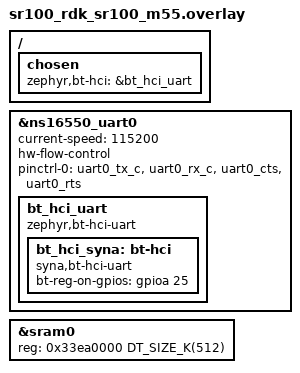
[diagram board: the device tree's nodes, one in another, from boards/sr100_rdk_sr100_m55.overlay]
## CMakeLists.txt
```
# Copyright (c) 2026 Synaptics Incorporated
#
# SPDX-License-Identifier: Apache-2.0

cmake_minimum_required(VERSION 3.20.0)
find_package(Zephyr REQUIRED HINTS $ENV{ZEPHYR_BASE})
project(bap_unicast_client)

target_include_directories(app PRIVATE
	$ENV{ZEPHYR_BASE}/samples/bluetooth/bap_unicast_client/src/
)

target_sources(app PRIVATE
	src/main.c
	src/stream_tx.c
)

# Use upstream LC3 encoder when liblc3 is available; fall back to stub otherwise
if(CONFIG_LIBLC3)
  target_sources(app PRIVATE
    $ENV{ZEPHYR_BASE}/samples/bluetooth/bap_unicast_client/src/stream_lc3.c
  )
else()
  target_sources(app PRIVATE src/stream_lc3.c)
endif()
```

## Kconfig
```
# Copyright (c) 2025 Nordic Semiconductor ASA
# Copyright (c) 2026 Synaptics Incorporated
#
# SPDX-License-Identifier: Apache-2.0

mainmenu "Bluetooth: BAP Unicast Client (SR110 RDK)"

config INFO_REPORTING_INTERVAL
	int "Number of SDUs received between each information report"
	default 1000
	help
	  Determines how often information about received data is logged.
	  Set to 0 to disable reporting.

config BT_BAP_AUTO_CONNECT
	bool "Auto-connect without user interaction"
	default n
	help
	  When enabled, scan_and_connect() selects a device automatically
	  after the scan timeout without waiting for console input.

	  If CONFIG_BT_BAP_AUTO_CONNECT_ADDR is non-empty, the sample
	  connects directly to that address (skipping the scan list).
	  Otherwise it selects the device with the strongest RSSI from
	  the scan results.

	  Useful for automated testing where no one is at the UART console
	  to type a device selection.

config BT_BAP_AUTO_CONNECT_ADDR
	string "Fixed peer Bluetooth address for auto-connect"
	default ""
	help
	  Used only when CONFIG_BT_BAP_AUTO_CONNECT=y.
	  If non-empty, the sample will connect directly to this address
	  (format: "XX:XX:XX:XX:XX:XX").
	  Leave empty to auto-select the device with the strongest RSSI.

source "Kconfig.zephyr"
```

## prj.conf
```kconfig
CONFIG_BT=y
CONFIG_LOG=y
CONFIG_BT_SMP=y
CONFIG_BT_CENTRAL=y
CONFIG_BT_ISO_CENTRAL=y
CONFIG_BT_GATT_CLIENT=y
CONFIG_BT_GATT_AUTO_DISCOVER_CCC=y
CONFIG_BT_GATT_AUTO_UPDATE_MTU=y
CONFIG_UTF8=y
CONFIG_BT_AUDIO=y
CONFIG_BT_BAP_UNICAST_CLIENT=y
CONFIG_BT_ISO_TX_BUF_COUNT=8
CONFIG_BT_ISO_MAX_CHAN=4
CONFIG_BT_BAP_UNICAST_CLIENT_GROUP_STREAM_COUNT=4
CONFIG_BT_BAP_UNICAST_CLIENT_ASE_SNK_COUNT=2
CONFIG_BT_BAP_UNICAST_CLIENT_ASE_SRC_COUNT=0
CONFIG_BT_KEYS_OVERWRITE_OLDEST=y
CONFIG_BT_EXT_ADV=y

# LC3 encoder — generates sine wave audio sent over ISO
CONFIG_LIBLC3=y
CONFIG_FPU=y
CONFIG_FPU_SHARING=y

# LC3 TX thread needs a larger stack (encoder uses ~2KB)
CONFIG_BT_ISO_TX_MTU=155

# Interactive device selection
CONFIG_CONSOLE_SUBSYS=y
CONFIG_CONSOLE_GETLINE=y

# ── SR110 + SYNA hardware ─────────────────────────────────────────────────
CONFIG_BT_H4=y
CONFIG_BT_HCI_SYNA=y
CONFIG_GPIO=y
CONFIG_UART_INTERRUPT_DRIVEN=y
CONFIG_UART_NS16550_VARIANT_NS16750=y
CONFIG_SRAM_SIZE=512
CONFIG_MAIN_STACK_SIZE=4096
CONFIG_BT_RX_STACK_SIZE=4096
CONFIG_BT_BUF_CMD_TX_SIZE=255

# Debug: enable ISO and BAP ISO logging to diagnose data path setup failures
CONFIG_BT_ISO_LOG_LEVEL_DBG=y
CONFIG_BT_BAP_ISO_LOG_LEVEL_DBG=y
CONFIG_XIP=n
```

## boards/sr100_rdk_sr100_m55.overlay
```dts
/*
 * Copyright (c) 2026 Synaptics Incorporated
 *
 * SPDX-License-Identifier: Apache-2.0
 */

/ {
	chosen {
		zephyr,bt-hci = &bt_hci_uart;
	};
};

&ns16550_uart0 {
	status = "okay";
	current-speed = <115200>;
	hw-flow-control;
	pinctrl-0 = <&uart0_tx_c &uart0_rx_c &uart0_cts &uart0_rts>;
	pinctrl-names = "default";

	bt_hci_uart: bt_hci_uart {
		compatible = "zephyr,bt-hci-uart";
		status = "okay";

		bt_hci_syna: bt-hci {
			compatible = "syna,bt-hci-uart";
			status = "okay";
			bt-reg-on-gpios = <&gpioa 25 GPIO_ACTIVE_HIGH>;
		};
	};
};

/*
 * Extend SRAM to 512KB (0x33ea0000..0x33F20000).
 * 384KB is enough for normal BT samples, but bap_unicast_client with
 * liblc3 needs ~88KB extra for the LC3 lookup tables (rodata).
 * 0x33F20000 is the OpenOCD WORKAREA_ADDR — safe boundary for runtime.
 */
&sram0 {
	reg = <0x33ea0000 DT_SIZE_K(512)>;
	ranges = <0x0 0x33ea0000 DT_SIZE_K(512)>;
};
```

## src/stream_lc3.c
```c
/*
 * Copyright (c) 2026 Synaptics Incorporated
 *
 * SPDX-License-Identifier: Apache-2.0
 */

#include <errno.h>
#include <zephyr/net_buf.h>

/* Forward declaration matching stream_lc3.h opaque type */
struct tx_stream;

int stream_lc3_init(struct tx_stream *stream)
{
(void)stream;
return -ENOTSUP;
}

void stream_lc3_add_data(struct tx_stream *stream, struct net_buf *buf)
{
(void)stream;
(void)buf;
}
```

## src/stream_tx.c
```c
/*
 * Copyright (c) 2024-2025 Nordic Semiconductor ASA
 *
 * SPDX-License-Identifier: Apache-2.0
 */

#include <autoconf.h>
#include <errno.h>
#include <stdbool.h>
#include <stddef.h>
#include <stdint.h>

#include <zephyr/bluetooth/audio/cap.h>
#include <zephyr/bluetooth/audio/bap.h>
#include <zephyr/bluetooth/bluetooth.h>
#include <zephyr/bluetooth/hci_types.h>
#include <zephyr/bluetooth/iso.h>
#include <zephyr/kernel.h>
#include <zephyr/kernel/thread_stack.h>
#include <zephyr/logging/log.h>
#include <zephyr/logging/log_core.h>
#include <zephyr/net_buf.h>
#include <zephyr/sys/__assert.h>
#include <zephyr/sys/byteorder.h>
#include <zephyr/sys/util.h>
#include <zephyr/sys/util_macro.h>
#include <zephyr/types.h>

#include "stream_lc3.h"
#include "stream_tx.h"

LOG_MODULE_REGISTER(stream_tx, LOG_LEVEL_INF);

static struct tx_stream tx_streams[CONFIG_BT_BAP_UNICAST_CLIENT_ASE_SNK_COUNT];

static bool stream_is_streaming(const struct bt_bap_stream *bap_stream)
{
	struct bt_bap_ep_info ep_info;
	int err;

	if (bap_stream == NULL) {
		return false;
	}

	/* No-op if stream is not configured */
	if (bap_stream->ep == NULL) {
		return false;
	}

	err = bt_bap_ep_get_info(bap_stream->ep, &ep_info);
	if (err != 0) {
		return false;
	}

	return ep_info.state == BT_BAP_EP_STATE_STREAMING;
}

static void tx_thread_func(void *arg1, void *arg2, void *arg3)
{
	NET_BUF_POOL_FIXED_DEFINE(tx_pool, CONFIG_BT_ISO_TX_BUF_COUNT,
				  BT_ISO_SDU_BUF_SIZE(CONFIG_BT_ISO_TX_MTU),
				  CONFIG_BT_CONN_TX_USER_DATA_SIZE, NULL);
	static uint8_t mock_data[CONFIG_BT_ISO_TX_MTU];

	for (size_t i = 0U; i < ARRAY_SIZE(mock_data); i++) {
		mock_data[i] = (uint8_t)i;
	}

	/* This loop will attempt to send on all streams in the streaming state in a round robin
	 * fashion.
	 * The TX is controlled by the number of buffers configured, and increasing
	 * CONFIG_BT_ISO_TX_BUF_COUNT will allow for more streams in parallel, or to submit more
	 * buffers per stream.
	 * Once a buffer has been freed by the stack, it triggers the next TX.
	 */
	while (true) {
		bool any_sent = false;

		for (size_t i = 0U; i < ARRAY_SIZE(tx_streams); i++) {
			struct bt_bap_stream *bap_stream = tx_streams[i].bap_stream;

			if (stream_is_streaming(bap_stream)) {
				uint16_t sdu_len;
				struct net_buf *buf;

				buf = net_buf_alloc(&tx_pool, K_NO_WAIT);
				if (buf == NULL) {
					/* No buffer available for this stream right now.
					 * Skip so the other stream is not starved.
					 */
					continue;
				}
				net_buf_reserve(buf, BT_ISO_CHAN_SEND_RESERVE);

				if (IS_ENABLED(CONFIG_LIBLC3) &&
				    bap_stream->codec_cfg->id == BT_HCI_CODING_FORMAT_LC3) {
					stream_lc3_add_data(&tx_streams[i], buf);
				} else {
					__ASSERT(bap_stream->qos->sdu <= ARRAY_SIZE(mock_data),
						 "Configured codec SDU len %u does not match mock "
						 "data size %zu",
						 bap_stream->qos->sdu, ARRAY_SIZE(mock_data));
					net_buf_add_mem(buf, mock_data, bap_stream->qos->sdu);
				}

				sdu_len = buf->len;

				int err = bt_bap_stream_send(bap_stream, buf, tx_streams[i].seq_num);

				if (err == 0) {
					tx_streams[i].seq_num++;
					any_sent = true;

					if (CONFIG_INFO_REPORTING_INTERVAL > 0 &&
					    (tx_streams[i].seq_num %
					     CONFIG_INFO_REPORTING_INTERVAL) == 0U) {
						LOG_INF("Stream %p: Sent %u total SDUs of size %u",
							bap_stream, tx_streams[i].seq_num, sdu_len);
					}
				} else {
					LOG_ERR("Unable to send: %d", err);
					net_buf_unref(buf);
				}
			} /* No-op if stream is not streaming */
		}

		if (!any_sent) {
			/* No stream was able to send — wait briefly for buffers or stream state */
			k_sleep(K_MSEC(1));
		}
	}
}

int stream_tx_register(struct bt_bap_stream *bap_stream)
{
	if (bap_stream == NULL) {
		return -EINVAL;
	}

	for (size_t i = 0U; i < ARRAY_SIZE(tx_streams); i++) {
		if (tx_streams[i].bap_stream == NULL) {
			tx_streams[i].bap_stream = bap_stream;
			tx_streams[i].seq_num = 0U;

			if (IS_ENABLED(CONFIG_LIBLC3) &&
			    bap_stream->codec_cfg->id == BT_HCI_CODING_FORMAT_LC3) {
				const int err = stream_lc3_init(&tx_streams[i]);

				if (err != 0) {
					tx_streams[i].bap_stream = NULL;

					return err;
				}
			}

			LOG_INF("Registered %p for TX", bap_stream);
			if (bap_stream->qos->sdu > CONFIG_BT_ISO_TX_MTU) {
				LOG_WRN("Stream configured for SDUs larger (%u) than "
					"CONFIG_BT_ISO_TX_MTU (%d)",
					bap_stream->qos->sdu, CONFIG_BT_ISO_TX_MTU);
			}

			return 0;
		}
	}

	return -ENOMEM;
}

int stream_tx_unregister(struct bt_bap_stream *bap_stream)
{
	if (bap_stream == NULL) {
		return -EINVAL;
	}

	for (size_t i = 0U; i < ARRAY_SIZE(tx_streams); i++) {
		if (tx_streams[i].bap_stream == bap_stream) {
			tx_streams[i].bap_stream = NULL;

			LOG_INF("Unregistered %p for TX", bap_stream);

			return 0;
		}
	}

	return -ENODATA;
}

void stream_tx_init(void)
{
	static bool thread_started;

	if (!thread_started) {
		static K_KERNEL_STACK_DEFINE(tx_thread_stack,
					     IS_ENABLED(CONFIG_LIBLC3) ? 4096U : 1024U);
		const int tx_thread_prio = K_PRIO_PREEMPT(5);
		static struct k_thread tx_thread;

		k_thread_create(&tx_thread, tx_thread_stack, K_KERNEL_STACK_SIZEOF(tx_thread_stack),
				tx_thread_func, NULL, NULL, NULL, tx_thread_prio, 0, K_NO_WAIT);
		k_thread_name_set(&tx_thread, "TX thread");
		thread_started = true;
	}
}
```
